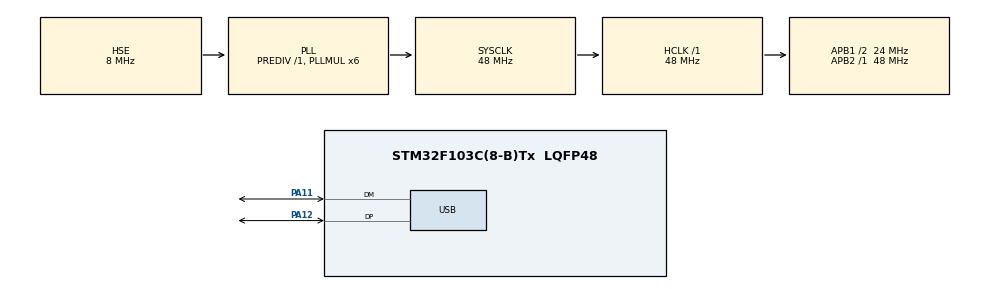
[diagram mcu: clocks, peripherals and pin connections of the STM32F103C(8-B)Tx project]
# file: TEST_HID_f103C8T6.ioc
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Mcu.Family=STM32F1
PC15-OSC32_OUT.Mode=LSE-External-Oscillator
USB_DEVICE.CLASS_NAME_FS=CUSTOM_HID
PD1-OSC_OUT.Mode=HSE-External-Oscillator
USB_DEVICE.VirtualModeFS=Custom_Hid_FS
VP_USB_DEVICE_VS_USB_DEVICE_CUSTOM_HID_FS.Mode=CUSTOM_HID_FS
PA11.Mode=Device
PD0-OSC_IN.Signal=RCC_OSC_IN
RCC.APB1CLKDivider=RCC_HCLK_DIV2
PC14-OSC32_IN.Signal=RCC_OSC32_IN
RCC.SYSCLKSource=RCC_SYSCLKSOURCE_PLLCLK
ProjectManager.StackSize=0x400
PD1-OSC_OUT.Signal=RCC_OSC_OUT
PA13.Signal=SYS_JTMS-SWDIO
PA12.Signal=USB_DP
ProjectManager.TargetToolchain=STM32CubeIDE
RCC.HCLKFreq_Value=48000000
RCC.APB2TimFreq_Value=48000000
RCC.USBFreq_Value=48000000
PC15-OSC32_OUT.Signal=RCC_OSC32_OUT
RCC.AHBFreq_Value=48000000
PD0-OSC_IN.Mode=HSE-External-Oscillator
board=custom
RCC.PLLMUL=RCC_PLL_MUL6
RCC.APB2Freq_Value=48000000
PC14-OSC32_IN.Mode=LSE-External-Oscillator
PA14.Mode=Serial_Wire
NVIC.USB_LP_CAN1_RX0_IRQn=true\:0\:0\:false\:false\:true\:false\:true
PA13.Mode=Serial_Wire
Mcu.Name=STM32F103C(8-B)Tx
RCC.SYSCLKFreq_VALUE=48000000
Mcu.Package=LQFP48
PA12.Mode=Device
PA11.Signal=USB_DM
PA14.Signal=SYS_JTCK-SWCLK
ProjectManager.HeapSize=0x200
NVIC.PriorityGroup=NVIC_PRIORITYGROUP_4
RCC.APB1TimFreq_Value=48000000
RCC.APB1Freq_Value=24000000
USB_DEVICE.VirtualMode=CustomHid

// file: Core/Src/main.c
/* USER CODE BEGIN Header */
/**
 ******************************************************************************
 * @file           : main.c
 * @brief          : Main program body
 ******************************************************************************
 * @attention
 *
 * <h2><center>&copy; Copyright (c) 2021 STMicroelectronics.
 * All rights reserved.</center></h2>
 *
 * This software component is licensed by ST under BSD 3-Clause license,
 * the "License"; You may not use this file except in compliance with the
 * License. You may obtain a copy of the License at:
 *                        opensource.org/licenses/BSD-3-Clause
 *
 ******************************************************************************
 */
/* USER CODE END Header */
#include "main.h"
#include "usb_device.h"
#include "gpio.h"

/* USER CODE BEGIN Includes */
#include <stdbool.h>
#include "usbd_custom_hid_if.h"
/* USER CODE END Includes */

/* USER CODE BEGIN PV */
uint8_t hid_in_report[64];
uint8_t hid_out_report[64];
bool is_hid_out_empty = true;
/* USER CODE END PV */

void SystemClock_Config(void);

int main(void)
{

	/* MCU Configuration--------------------------------------------------------*/

	/* Reset of all peripherals, Initializes the Flash interface and the Systick. */
	HAL_Init();

	/* Configure the system clock */
	SystemClock_Config();

	/* Initialize all configured peripherals */
	MX_GPIO_Init();
	MX_USB_DEVICE_Init();

	/* Infinite loop */
	while (1)
	{

		/* USER CODE BEGIN 3 */
		if (is_hid_out_empty == false)
		{
			memcpy(hid_in_report, hid_out_report, 64);
			for (int i = 0; i < 64; i++)
			{
				hid_in_report[i] = hid_out_report[i];
			}
			USBD_CUSTOM_HID_SendReport_FS(hid_in_report, 64);
			is_hid_out_empty = true;
		}
		HAL_Delay(1);
	}
	/* USER CODE END 3 */
}

void SystemClock_Config(void)
{
	RCC_OscInitTypeDef RCC_OscInitStruct =
	{ 0 };
	RCC_ClkInitTypeDef RCC_ClkInitStruct =
	{ 0 };
	RCC_PeriphCLKInitTypeDef PeriphClkInit =
	{ 0 };

	/** Initializes the RCC Oscillators according to the specified parameters
	 * in the RCC_OscInitTypeDef structure.
	 */
	RCC_OscInitStruct.OscillatorType = RCC_OSCILLATORTYPE_HSE;
	RCC_OscInitStruct.HSEState = RCC_HSE_ON;
	RCC_OscInitStruct.HSEPredivValue = RCC_HSE_PREDIV_DIV1;
	RCC_OscInitStruct.HSIState = RCC_HSI_ON;
	RCC_OscInitStruct.PLL.PLLState = RCC_PLL_ON;
	RCC_OscInitStruct.PLL.PLLSource = RCC_PLLSOURCE_HSE;
	RCC_OscInitStruct.PLL.PLLMUL = RCC_PLL_MUL6;
	if (HAL_RCC_OscConfig(&RCC_OscInitStruct) != HAL_OK)
	{
		Error_Handler();
	}
	/** Initializes the CPU, AHB and APB buses clocks
	 */
	RCC_ClkInitStruct.ClockType = RCC_CLOCKTYPE_HCLK | RCC_CLOCKTYPE_SYSCLK
			| RCC_CLOCKTYPE_PCLK1 | RCC_CLOCKTYPE_PCLK2;
	RCC_ClkInitStruct.SYSCLKSource = RCC_SYSCLKSOURCE_PLLCLK;
	RCC_ClkInitStruct.AHBCLKDivider = RCC_SYSCLK_DIV1;
	RCC_ClkInitStruct.APB1CLKDivider = RCC_HCLK_DIV2;
	RCC_ClkInitStruct.APB2CLKDivider = RCC_HCLK_DIV1;

	if (HAL_RCC_ClockConfig(&RCC_ClkInitStruct, FLASH_LATENCY_1) != HAL_OK)
	{
		Error_Handler();
	}
	PeriphClkInit.PeriphClockSelection = RCC_PERIPHCLK_USB;
	PeriphClkInit.UsbClockSelection = RCC_USBCLKSOURCE_PLL;
	if (HAL_RCCEx_PeriphCLKConfig(&PeriphClkInit) != HAL_OK)
	{
		Error_Handler();
	}
}

void Error_Handler(void)
{
	__disable_irq();
	while (1)
	{
	}
}

/************************ (C) COPYRIGHT STMicroelectronics *****END OF FILE****/
